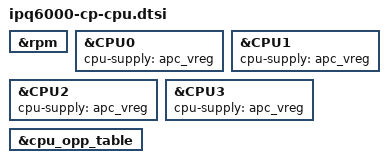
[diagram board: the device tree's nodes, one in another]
// SPDX-License-Identifier: GPL-2.0-only

#include "ipq6018-cpr-regulator.dtsi"

&rpm {
	status = "okay";
};

&CPU0 {
	cpu-supply = <&apc_vreg>;
};

&CPU1 {
	cpu-supply = <&apc_vreg>;
};

&CPU2 {
	cpu-supply = <&apc_vreg>;
};

&CPU3 {
	cpu-supply = <&apc_vreg>;
};

&cpu_opp_table {
	/delete-node/ opp-1608000000;
	/delete-node/ opp-1800000000;
};
